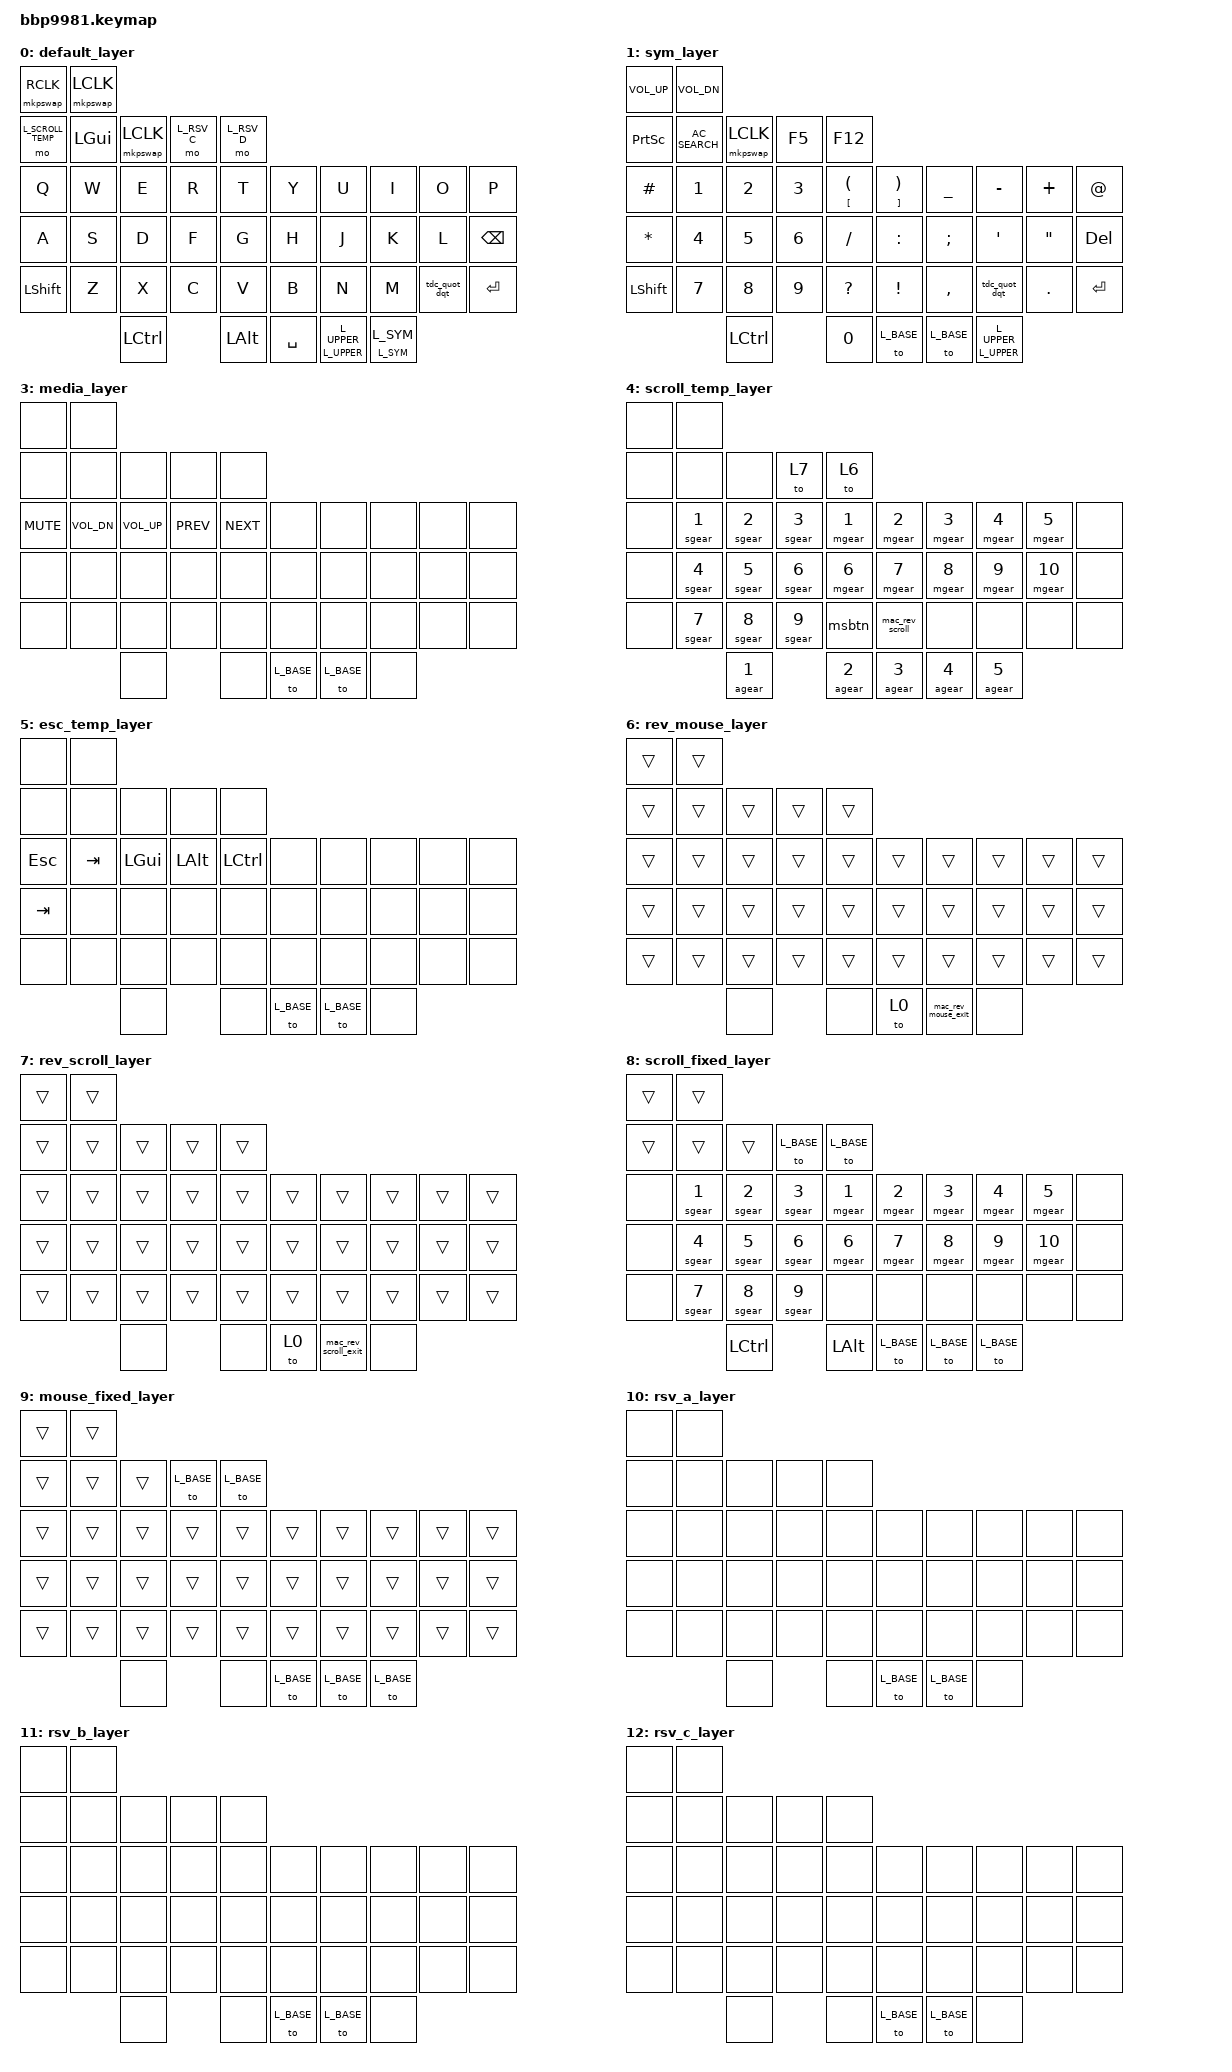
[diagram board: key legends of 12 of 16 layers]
/*
 * 9981-Pro — ZMK Keymap
 * =======================
 * S6 16-layer keymap spec (2026-05-27) — Phase 4 R8
 *
 * Layer architecture:
 *   L_BASE          0   Default (alphanumeric, plain keys)
 *   L_SYM           1   Symbols / numbers
 *   L_UPPER         2   System control: BT + backlight + RGB + USB output
 *   L_MEDIA         3   Media controls (volume, playback)
 *   L_SCROLL_TEMP   4   Scroll + gear selection (sgear 1-9, mgear 1-10, agear 1-5)
 *   L_ESC_TEMP      5   ESC + shortcuts, scroll mode
 *   L_REV_MOUSE     6   Reverse mouse (transparent, 1 exit key, red RGB)
 *   L_REV_SCROLL    7   Reverse scroll (transparent, 1 exit key, blue RGB)
 *   L_SCROLL_FIXED  8   Scroll fixed mode (to, not mo)
 *   L_MOUSE_FIXED   9   Mouse fixed mode (to, not mo)
 *   L_RSV_A         10  Reserved
 *   L_RSV_B         11  Reserved
 *   L_RSV_C         12  Reserved
 *   L_RSV_D         13  Reserved
 *   L_RSV_E         14  Reserved
 *   L_RSV_F         15  Reserved
 *
 * SPDX-License-Identifier: MIT
 */

#include <dt-bindings/zmk/mouse.h>
#include <behaviors.dtsi>
#include <dt-bindings/zmk/bt.h>
#include <dt-bindings/zmk/keys.h>
#include <dt-bindings/zmk/outputs.h>
#include <dt-bindings/zmk/pointing.h>
#include <dt-bindings/zmk/rgb.h>

/* ==============================================================
 *  LAYER DEFINITIONS  —  16-layer (Phase 4 R8)
 * ============================================================== */

#define L_BASE          0
#define L_SYM           1
#define L_UPPER         2
#define L_MEDIA         3
#define L_SCROLL_TEMP   4
#define L_ESC_TEMP      5
#define L_REV_MOUSE     6
#define L_REV_SCROLL    7
#define L_SCROLL_FIXED  8
#define L_MOUSE_FIXED   9
#define L_RSV_A         10
#define L_RSV_B         11
#define L_RSV_C         12
#define L_RSV_D         13
#define L_RSV_E         14
#define L_RSV_F         15

/* Convenience macro for mode-6 (hold MO / tap SL) */

#define SL_MO(layer) &sl_mo layer layer

/* ==============================================================
 *  GLOBAL STICKY-LAYER TIMEOUT
 * ============================================================== */

&sl { release-after-ms = <3000>; };

/* ==============================================================
 *  BEHAVIORS
 * ============================================================== */

/ {
    /* ---- Tap dances ---- */

    behaviors {
        td0: tap_dance_0 {
            compatible = "zmk,behavior-tap-dance";
            #binding-cells = <0>;
            tapping-term-ms = <400>;
            bindings = <&mkpswap LCLK>, <&bt_clr>;
        };
    };

    behaviors {
        td_boot_out: td_boot_out {
            compatible = "zmk,behavior-tap-dance";
            #binding-cells = <0>;
            tapping-term-ms = <400>;
            bindings = <&bootloader>, <&out OUT_TOG>;
        };
    };

    behaviors {
        tdc_quot_dqt: td_quot_dqt {
            compatible = "zmk,behavior-tap-dance";
            #binding-cells = <0>;
            tapping-term-ms = <400>;
            bindings = <&kp APOS>, <&kp DQT>;
        };
    };

    behaviors {
        tdc_to_MEDIA: td_mute_to_layer {
            compatible = "zmk,behavior-tap-dance";
            #binding-cells = <0>;
            tapping-term-ms = <400>;
            bindings = <&kp C_MUTE>, <&to L_MEDIA>;
        };
    };

    /* ---- Homerow mods ---- */

    behaviors {
        hm: homerow_mods {
            compatible = "zmk,behavior-hold-tap";
            #binding-cells = <2>;
            tapping-term-ms = <400>;
            bindings = <&kp &kp>;
        };
    };

    behaviors {
        bhm: balanced_homerow_mods {
            compatible = "zmk,behavior-hold-tap";
            #binding-cells = <2>;
            flavor = "balanced";
            tapping-term-ms = <400>;
            bindings = <&kp>, <&kp>;
        };
    };

    /* ---- Hold-Tap: bracket/paren ---- */

    behaviors {
        ht_bp: behavior_ht_bp {
            compatible = "zmk,behavior-hold-tap";
            #binding-cells = <2>;
            flavor = "hold-preferred";
            tapping-term-ms = <200>;
            bindings = <&kp &kp>;
        };
    };

    /* ---- Mode 6: hold = MO, tap = SL ---- */

    behaviors {
        sl_mo: behavior_sl_mo {
            compatible = "zmk,behavior-hold-tap";
            #binding-cells = <2>;
            flavor = "hold-preferred";
            tapping-term-ms = <450>;
            bindings = <&mo &sl>;
        };
    };

    /* ---- Sticky key ---- */

    behaviors {
        sk_kp: behavior_sk_kp {
            compatible = "zmk,behavior-hold-tap";
            #binding-cells = <2>;
            flavor = "hold-preferred";
            tapping-term-ms = <450>;
            bindings = <&kp &sk>;
        };
    };

    /* ---- Mode 3: hold = toggle, tap = NONE ---- */

    behaviors {
        ht_tog: behavior_ht_tog {
            compatible = "zmk,behavior-hold-tap";
            #binding-cells = <2>;
            flavor = "hold-preferred";
            tapping-term-ms = <450>;
            bindings = <&tog &kp>;
        };
    };

    /* ---- Mode 4: hold = toggle, tap = sticky ---- */

    behaviors {
        sl_tog: behavior_sl_tog {
            compatible = "zmk,behavior-hold-tap";
            #binding-cells = <2>;
            flavor = "hold-preferred";
            tapping-term-ms = <450>;
            bindings = <&tog &sl>;
        };
    };

    /* ---- Sensor gear behaviors ---- */

    behaviors {
        mgear: mgear {
            compatible = "zmk,behavior-sensor-gear";
            #binding-cells = <1>;
            gear-type = "mouse";
            min-gear = <1>;
            max-gear = <10>;
        };

        sgear: sgear {
            compatible = "zmk,behavior-sensor-gear";
            #binding-cells = <1>;
            gear-type = "scroll";
            min-gear = <1>;
            max-gear = <9>;
        };

        /* ---- Mouse button swap behavior ---- */

        msbtn: msbtn {
            compatible = "zmk,behavior-swap-buttons";
            #binding-cells = <0>;
        };

        mkpswap: mkpswap {
            compatible = "zmk,behavior-mouse-key-press-swap";
            #binding-cells = <1>;
        };

        agear: agear {
            compatible = "zmk,behavior-sensor-gear";
            #binding-cells = <1>;
            gear-type = "accel";
            min-gear = <1>;
            max-gear = <5>;
        };

        bt_clr: bt_clr {
            compatible = "zmk,behavior-bt-clr";
            #binding-cells = <0>;
        };
    };

    /* ==============================================================
     *  MACROS  —  4 RGB reverse-layer macros
     * ============================================================== */

    macros {
        /* Reverse-mouse: toggle to L_REV_MOUSE + set red RGB */

        mac_rev_mouse: macro_rev_mouse {
            compatible = "zmk,behavior-macro";
            #binding-cells = <0>;
            bindings = <&tog L_REV_MOUSE &rgb_ug RGB_COLOR_HSB(0,100,100)>;
        };

        /* Exit reverse-mouse: toggle off + RGB off */

        mac_rev_mouse_exit: macro_rev_mouse_exit {
            compatible = "zmk,behavior-macro";
            #binding-cells = <0>;
            bindings = <&tog L_REV_MOUSE &rgb_ug RGB_OFF>;
        };

        /* Reverse-scroll: toggle to L_REV_SCROLL + set blue RGB */

        mac_rev_scroll: macro_rev_scroll {
            compatible = "zmk,behavior-macro";
            #binding-cells = <0>;
            bindings = <&tog L_REV_SCROLL &rgb_ug RGB_COLOR_HSB(240,100,100)>;
        };

        /* Exit reverse-scroll: toggle off + RGB off */

        mac_rev_scroll_exit: macro_rev_scroll_exit {
            compatible = "zmk,behavior-macro";
            #binding-cells = <0>;
            bindings = <&tog L_REV_SCROLL &rgb_ug RGB_OFF>;
        };
    };

    /* ==============================================================
     *  COMBOS
     * ============================================================== */

    combos {
        compatible = "zmk,combos";

        /* SRS combo: key-positions 10 19 (R+D), triggers combo layer */

        combo_rsv_1 {
            timeout-ms = <50>;
            key-positions = <10 19>;
            bindings = <&mo L_RSV_A>;
        };
    };

    /* ==============================================================
     *  KEYMAP  —  12 layers (0–11)
     * ============================================================== */

    keymap {
        compatible = "zmk,keymap";

        /* -----------------------------------------------------------------
         *  Layer 0  —  L_BASE  (Default QWERTY)
         *
         *  Row order: shoulder(2), row2(5), Q-row(10), A-row(10), Z-row(10),
         *             bottom(5)  =  42 keys total
         * ----------------------------------------------------------------- */

        default_layer {
            bindings = <
&mkpswap RCLK          &mkpswap LCLK
&mo L_SCROLL_TEMP      &kp LGUI   &mkpswap LCLK  &mo L_RSV_C  &mo L_RSV_D
&kp Q                  &kp W      &kp E          &kp R        &kp T        &kp Y        &kp U                   &kp I               &kp O          &kp P
&kp A              &kp S      &kp D      &kp F        &kp G        &kp H        &kp J                   &kp K               &kp L          &kp BSPC
&kp LSHFT          &kp Z      &kp X      &kp C        &kp V        &kp B        &kp N                   &kp M               &tdc_quot_dqt  &kp ENTER
                              &kp LCTRL               &kp LALT     &kp SPACE    &sl_mo L_UPPER L_UPPER  &sl_mo L_SYM L_SYM
            >;
        };

        /* -----------------------------------------------------------------
         *  Layer 1  —  L_SYM  (Symbols / Numbers)
         * ----------------------------------------------------------------- */

        sym_layer {
            bindings = <
&kp C_VOL_UP  &kp C_VOL_DN
&kp PSCRN     &kp C_AC_SEARCH  &mkpswap LCLK  &kp F5  &kp F12
&kp HASH      &kp N1           &kp N2     &kp N3  &ht_bp LBKT LPAR  &ht_bp RBKT RPAR    &kp UNDER   &kp MINUS               &kp PLUS  &kp AT
&kp STAR      &kp N4           &kp N5     &kp N6  &kp SLASH         &kp COLON           &kp SEMI    &kp APOS                &kp DQT   &kp DEL
&kp LSHFT     &kp N7           &kp N8     &kp N9  &kp QMARK         &kp EXCL            &kp COMMA   &tdc_quot_dqt           &kp DOT   &kp ENTER
                               &kp LCTRL          &kp N0            &to L_BASE          &to L_BASE  &sl_mo L_UPPER L_UPPER
            >;
        };

        /* -----------------------------------------------------------------
         *  Layer 2  —  L_UPPER  (System Control)
         * ----------------------------------------------------------------- */

        upper_layer {
            bindings = <
&kp C_BRI_DN  &kp C_BRI_UP
&bt BT_SEL 0  &bt BT_SEL 1     &bt BT_SEL 2       &bt BT_SEL 3  &bt_clr
&kp C_BRI_UP  &rgb_ug RGB_BRI  &rgb_ug RGB_EFF  &out OUT_TOG  &td_boot_out  &kp C_BRI_DN    &rgb_ug RGB_BRD  &rgb_ug RGB_EFR  &none       &none
&kp C_BRI_DN  &none            &none            &none         &none         &none           &none            &to L_BASE       &to L_BASE  &none
            >;
        };

        /* -----------------------------------------------------------------
         *  Layer 3  —  L_MEDIA  (Media Controls)
         * ----------------------------------------------------------------- */

        media_layer {
            bindings = <
&none       &none
&none       &none         &none         &none       &none
&kp C_MUTE  &kp C_VOL_DN  &kp C_VOL_UP  &kp C_PREV  &kp C_NEXT  &none         &none       &none  &none  &none
&none       &none         &none         &none       &none       &none         &none       &none  &none  &none
&none       &none         &none         &none       &none       &none         &none       &none  &none  &none
                          &none                     &none       &to L_BASE    &to L_BASE  &none
            >;
        };

        /* -----------------------------------------------------------------
         *  Layer 4  —  L_SCROLL_TEMP  (Gear Selection + Scroll Mode)
         *
         *  sgear: W=1, E=2, R=3, S=4, D=5, F=6, X=7, C=8, V=9
         *  mgear: T=1, Y=2, U=3, I=4, O=5, G=6, H=7, J=8, K=9, L=10
         *  agear (accel profile): bottom row slow→aggressive: 1→5
         * ----------------------------------------------------------------- */

        scroll_temp_layer {
            bindings = <
&none  &none
&none  &none     &none      &to 7     &to 6
&none  &sgear 1  &sgear 2   &sgear 3  &mgear 1  &mgear 2          &mgear 3         &mgear 4    &mgear 5   &none
&none  &sgear 4  &sgear 5   &sgear 6  &mgear 6  &mgear 7          &mgear 8         &mgear 9    &mgear 10  &none
&none  &sgear 7  &sgear 8   &sgear 9  &msbtn             &mac_rev_scroll    &none            &none       &none      &none
                 &agear 1             &agear 2  &agear 3          &agear 4          &agear 5
            >;
        };

        /* -----------------------------------------------------------------
         *  Layer 5  —  L_ESC_TEMP  (ESC + Shortcuts, Scroll Mode)
         * ----------------------------------------------------------------- */

        esc_temp_layer {
            bindings = <
&none    &none
&none    &none    &none     &none     &none
&kp ESC  &kp TAB  &kp LGUI  &kp LALT  &kp LCTRL  &none         &none       &none  &none  &none
&kp TAB  &none    &none     &none     &none      &none         &none       &none  &none  &none
&none    &none    &none     &none     &none      &none         &none       &none  &none  &none
                  &none               &none      &to L_BASE    &to L_BASE  &none
            >;
        };

        /* -----------------------------------------------------------------
         *  Layer 6  —  L_REV_MOUSE  (Reverse Mouse — Transparent)
         *
         *  All keys &trans (shoulders, row2, Q-row, A-row, Z-row).
         *  Only exit macro key on bottom row is non-transparent.
         * ----------------------------------------------------------------- */

        rev_mouse_layer {
            bindings = <
&trans  &trans
&trans  &trans  &trans  &trans  &trans
&trans  &trans  &trans  &trans  &trans  &trans    &trans               &trans  &trans  &trans
&trans  &trans  &trans  &trans  &trans  &trans    &trans               &trans  &trans  &trans
&trans  &trans  &trans  &trans  &trans  &trans    &trans               &trans  &trans  &trans
                &none           &none   &to 0     &mac_rev_mouse_exit  &none
            >;
        };

        /* -----------------------------------------------------------------
         *  Layer 7  —  L_REV_SCROLL  (Reverse Scroll — Transparent)
         *
         *  All keys &trans (shoulders, row2, Q-row, A-row, Z-row).
         *  Only exit macro key on bottom row is non-transparent.
         * ----------------------------------------------------------------- */

        rev_scroll_layer {
            bindings = <
&trans  &trans
&trans  &trans  &trans  &trans  &trans
&trans  &trans  &trans  &trans  &trans  &trans    &trans                &trans  &trans  &trans
&trans  &trans  &trans  &trans  &trans  &trans    &trans                &trans  &trans  &trans
&trans  &trans  &trans  &trans  &trans  &trans    &trans                &trans  &trans  &trans
                &none           &none   &to 0     &mac_rev_scroll_exit  &none
            >;
        };

        /* -----------------------------------------------------------------
         *  Layer 8  —  L_SCROLL_FIXED  (Scroll Fixed Mode)
         *
         *  Like L_SCROLL_TEMP but stays in scroll mode (to-based).
         *  Touchpad in scroll mode. Shoulders transparent.
         *  Same sgear/mgear layout as L_SCROLL_TEMP.
         * ----------------------------------------------------------------- */

        scroll_fixed_layer {
            bindings = <
&trans       &trans
&trans       &trans  &trans  &to L_BASE     &to L_BASE
&none        &sgear 1  &sgear 2   &sgear 3  &mgear 1  &mgear 2          &mgear 3         &mgear 4    &mgear 5   &none
&none        &sgear 4  &sgear 5   &sgear 6  &mgear 6  &mgear 7          &mgear 8         &mgear 9    &mgear 10  &none
&none        &sgear 7  &sgear 8   &sgear 9  &none     &none             &none            &none       &none      &none
                        &kp LCTRL            &kp LALT  &to L_BASE       &to L_BASE       &to L_BASE
            >;
        };

        /* -----------------------------------------------------------------
         *  Layer 9  —  L_MOUSE_FIXED  (Mouse Fixed Mode)
         *
         *  Normal mouse mode that stays. Mostly transparent.
         *  Touchpad in normal mouse mode. Shoulders transparent.
         *  Bottom row: exit keys.
         * ----------------------------------------------------------------- */

        mouse_fixed_layer {
            bindings = <
&trans  &trans
&trans  &trans  &trans  &to L_BASE  &to L_BASE
&trans  &trans  &trans  &trans  &trans  &trans         &trans       &trans  &trans  &trans
&trans  &trans  &trans  &trans  &trans  &trans         &trans       &trans  &trans  &trans
&trans  &trans  &trans  &trans  &trans  &trans         &trans       &trans  &trans  &trans
                &none           &none   &to L_BASE    &to L_BASE  &to L_BASE
            >;
        };

        /* -----------------------------------------------------------------
         *  Layer 10  —  L_RSV_A  (Reserved)
         * ----------------------------------------------------------------- */

        rsv_a_layer {
            bindings = <
&none  &none
&none  &none  &none  &none  &none
&none  &none  &none  &none  &none  &none         &none       &none  &none  &none
&none  &none  &none  &none  &none  &none         &none       &none  &none  &none
&none  &none  &none  &none  &none  &none         &none       &none  &none  &none
              &none         &none  &to L_BASE    &to L_BASE  &none
            >;
        };

        /* -----------------------------------------------------------------
         *  Layer 11  —  L_RSV_B  (Reserved)
         * ----------------------------------------------------------------- */

        rsv_b_layer {
            bindings = <
&none  &none
&none  &none  &none  &none  &none
&none  &none  &none  &none  &none  &none         &none       &none  &none  &none
&none  &none  &none  &none  &none  &none         &none       &none  &none  &none
&none  &none  &none  &none  &none  &none         &none       &none  &none  &none
              &none         &none  &to L_BASE    &to L_BASE  &none
            >;
        };

        /* -----------------------------------------------------------------
         *  Layer 12  —  L_RSV_C  (Reserved)
         * ----------------------------------------------------------------- */

        rsv_c_layer {
            bindings = <
&none  &none
&none  &none  &none  &none  &none
&none  &none  &none  &none  &none  &none         &none       &none  &none  &none
&none  &none  &none  &none  &none  &none         &none       &none  &none  &none
&none  &none  &none  &none  &none  &none         &none       &none  &none  &none
              &none         &none  &to L_BASE    &to L_BASE  &none
            >;
        };

        /* -----------------------------------------------------------------
         *  Layer 13  —  L_RSV_D  (Reserved)
         * ----------------------------------------------------------------- */

        rsv_d_layer {
            bindings = <
&none  &none
&none  &none  &none  &none  &none
&none  &none  &none  &none  &none  &none         &none       &none  &none  &none
&none  &none  &none  &none  &none  &none         &none       &none  &none  &none
&none  &none  &none  &none  &none  &none         &none       &none  &none  &none
              &none         &none  &to L_BASE    &to L_BASE  &none
            >;
        };

        /* -----------------------------------------------------------------
         *  Layer 14  —  L_RSV_E  (Reserved)
         * ----------------------------------------------------------------- */

        rsv_e_layer {
            bindings = <
&none  &none
&none  &none  &none  &none  &none
&none  &none  &none  &none  &none  &none         &none       &none  &none  &none
&none  &none  &none  &none  &none  &none         &none       &none  &none  &none
&none  &none  &none  &none  &none  &none         &none       &none  &none  &none
              &none         &none  &to L_BASE    &to L_BASE  &none
            >;
        };

        /* -----------------------------------------------------------------
         *  Layer 15  —  L_RSV_F  (Reserved)
         * ----------------------------------------------------------------- */

        rsv_f_layer {
            bindings = <
&none  &none
&none  &none  &none  &none  &none
&none  &none  &none  &none  &none  &none         &none       &none  &none  &none
&none  &none  &none  &none  &none  &none         &none       &none  &none  &none
&none  &none  &none  &none  &none  &none         &none       &none  &none  &none
              &none         &none  &to L_BASE    &to L_BASE  &none
            >;
        };
    };
};
